VERSION "PT_K"

NS_ :

BS_:

BU_: BMS

BO_ 3221225472 VECTOR__INDEPENDENT_SIG_MSG: 0 Vector__XXX
 SG_ HVBTBDCSRQ_DlChDStReq : 0|4@0+ (1,0) [0|15] "" Vector__XXX
 SG_ HVBTBDCSRQ_DlChHStReq : 0|5@0+ (1,0) [0|31] "hr" Vector__XXX
 SG_ HVBTBDCSRQ_DlChMHStReq : 0|6@0+ (1,0) [0|63] "min" Vector__XXX
 SG_ HVBTBDCSRQ_DlChSsnStReq : 0|2@0+ (1,0) [0|3] "" Vector__XXX
 SG_ HVBTBDCSRQ_DlChSlStReq : 0|4@0+ (1,0) [0|15] "" Vector__XXX
 SG_ HVBTBRCSR_RtChDStReq : 0|4@0+ (1,0) [0|15] "" Vector__XXX
 SG_ HVBTBRCSR_RtChHStReq : 0|5@0+ (1,0) [0|31] "hr" Vector__XXX
 SG_ HVBTBRCSR_RtChMHStReq : 0|6@0+ (1,0) [0|63] "min" Vector__XXX
 SG_ HVBTBRCSR_RtChSsnStReq : 0|2@0+ (1,0) [0|3] "" Vector__XXX
 SG_ HVBTBRCSR_RtChSlRtStReq : 0|4@0+ (1,0) [0|15] "" Vector__XXX
 SG_ HVBTBRCSR_RtChSlStReq : 0|3@0+ (1,0) [0|7] "" Vector__XXX
 SG_ HVBTBRCSR_RtChSlTbRwReq : 0|3@0+ (1,0) [0|7] "rows" Vector__XXX

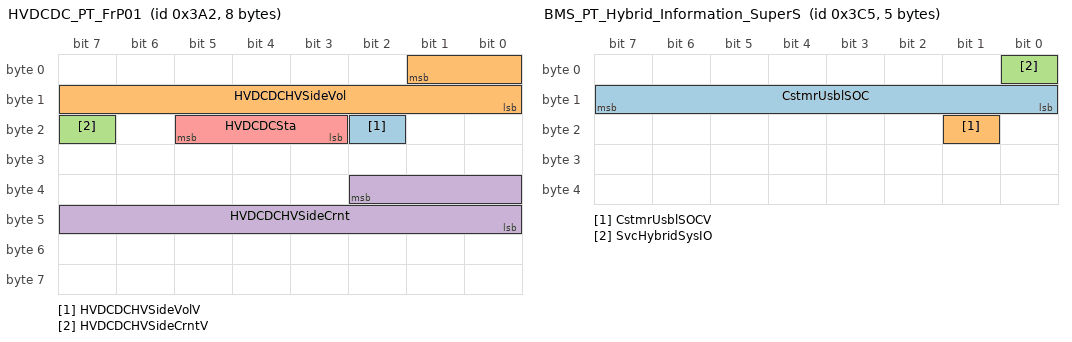
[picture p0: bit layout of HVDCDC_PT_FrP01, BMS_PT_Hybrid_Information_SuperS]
BO_ 930 HVDCDC_PT_FrP01: 8 Vector__XXX
 SG_ HVDCDCHVSideVolV : 18|1@0+ (1,0) [0|0] "l/min" Vector__XXX
 SG_ HVDCDCHVSideVol : 1|10@0+ (1,0) [0|0] "l/min" Vector__XXX
 SG_ HVDCDCHVSideCrntV : 23|1@0+ (1,0) [0|0] "l/min" Vector__XXX
 SG_ HVDCDCHVSideCrnt : 34|11@0+ (1,0) [0|0] "l/min" Vector__XXX
 SG_ HVDCDCSta : 21|3@0+ (1,0) [0|0] "l/min" Vector__XXX

BO_ 175 HCU_PT_FrP00: 8 Vector__XXX
 SG_ EPTStCmdOn : 17|1@0+ (1,0) [0|25.5] "l/min" Vector__XXX

BO_ 965 BMS_PT_Hybrid_Information_SuperS: 5 BMS
 SG_ CstmrUsblSOC : 15|8@0+ (0.39216,0) [0|100.0008] "%" Vector__XXX
 SG_ CstmrUsblSOCV : 17|1@0+ (1,0) [0|1] "" Vector__XXX
 SG_ SvcHybridSysIO : 0|1@0+ (1,0) [0|1] "" Vector__XXX

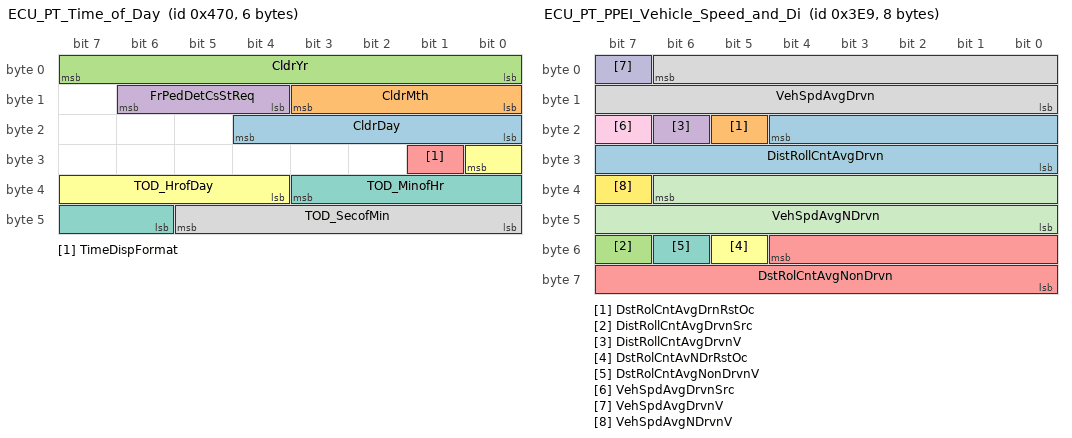
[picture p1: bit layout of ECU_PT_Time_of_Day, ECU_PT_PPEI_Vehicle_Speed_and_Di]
BO_ 1136 ECU_PT_Time_of_Day: 6 Vector__XXX
 SG_ CldrDay : 20|5@0+ (1,0) [0|31] "days"  BMS
 SG_ CldrMth : 11|4@0+ (1,0) [0|15] ""  BMS
 SG_ CldrYr : 7|8@0+ (1,2000) [2000|2255] "year"  BMS
 SG_ FrPedDetCsStReq : 14|3@0+ (1,0) [0|7] ""  BMS
 SG_ TimeDispFormat : 25|1@0+ (1,0) [0|1] ""  BMS
 SG_ TOD_HrofDay : 24|5@0+ (1,0) [0|31] "hr"  BMS
 SG_ TOD_MinofHr : 35|6@0+ (1,0) [0|63] "min"  BMS
 SG_ TOD_SecofMin : 45|6@0+ (1,0) [0|63] "s"  BMS

BO_ 497 ECU_PT_PPEI_Platform_General_Sta: 8 Vector__XXX
 SG_ ACCmpsrFldOn : 63|1@0+ (1,0) [0|1] ""  BMS
 SG_ ACCompModReq : 12|2@0+ (1,0) [0|3] ""  BMS
 SG_ ACCompNormLd : 55|8@0+ (0.1,0) [0|25.5] "l/min"  BMS
 SG_ ACCompNormLdV : 10|1@0+ (1,0) [0|1] ""  BMS
 SG_ SIRDpl : 58|1@0+ (1,0) [0|1] ""  BMS
 SG_ DispMeasSys : 59|1@0+ (1,0) [0|1] ""  BMS
 SG_ ElvtdIdlCstStReq : 33|2@0+ (1,0) [0|3] ""  BMS
 SG_ EngOilLfRstRq : 37|1@0+ (1,0) [0|1] ""  BMS
 SG_ FuelFltLfRstRqd : 56|1@0+ (1,0) [0|1] ""  BMS
 SG_ ImmblzrPreRelPswrd : 23|16@0+ (1,0) [0|65535] "passwrd"  BMS
 SG_ ImmblzrPreRelPswdStat : 8|1@0+ (1,0) [0|1] ""  BMS
 SG_ PrkBrkSwAtv : 36|1@0+ (1,0) [0|1] ""  BMS
 SG_ PMMAccTrmSt : 2|1@0+ (1,0) [0|1] ""  BMS
 SG_ PMMRunCrkTrmSt : 3|1@0+ (1,0) [0|1] ""  BMS
 SG_ RmVehStrRq : 15|1@0+ (1,0) [0|1] ""  BMS
 SG_ SysBkUpPwrMd : 5|2@0+ (1,0) [0|3] ""  BMS
 SG_ SysBkupPwrMdEn : 6|1@0+ (1,0) [0|1] ""  BMS
 SG_ SysBkUpPwrMdV : 46|1@0+ (1,0) [0|1] ""  BMS
 SG_ SysPwrMd : 1|2@0+ (1,0) [0|3] ""  BMS
 SG_ SysPwrMdV : 47|1@0+ (1,0) [0|1] ""  BMS
 SG_ ThrtlPrgrsnReq : 39|2@0+ (1,0) [0|3] ""  BMS
 SG_ TrStLgMdAtv : 34|1@0+ (1,0) [0|1] ""  BMS
 SG_ BkupPwrModeMstrVDA : 62|1@0+ (1,0) [0|1] ""  BMS
 SG_ ACCompSysVDA : 61|1@0+ (1,0) [0|1] ""  BMS
 SG_ AirbgVDA : 60|1@0+ (1,0) [0|1] ""  BMS

BO_ 1001 ECU_PT_PPEI_Vehicle_Speed_and_Di: 8 Vector__XXX
 SG_ DistRollCntAvgDrvn : 20|13@0+ (0.125,0) [0|1023.875] "m"  BMS
 SG_ DstRolCntAvgDrnRstOc : 21|1@0+ (1,0) [0|1] ""  BMS
 SG_ DistRollCntAvgDrvnSrc : 55|1@0+ (1,0) [0|1] ""  BMS
 SG_ DistRollCntAvgDrvnV : 22|1@0+ (1,0) [0|1] ""  BMS
 SG_ DstRolCntAvgNonDrvn : 52|13@0+ (0.125,0) [0|1023.875] "m"  BMS
 SG_ DstRolCntAvNDrRstOc : 53|1@0+ (1,0) [0|1] ""  BMS
 SG_ DstRolCntAvgNonDrvnV : 54|1@0+ (1,0) [0|1] ""  BMS
 SG_ VehSpdAvgDrvn : 6|15@0+ (0.015625,0) [0|511.984375] "km/h"  BMS
 SG_ VehSpdAvgDrvnSrc : 23|1@0+ (1,0) [0|1] ""  BMS
 SG_ VehSpdAvgDrvnV : 7|1@0+ (1,0) [0|1] ""  BMS
 SG_ VehSpdAvgNDrvn : 38|15@0+ (0.015625,0) [0|511.984375] "km/h"  BMS
 SG_ VehSpdAvgNDrvnV : 39|1@0+ (1,0) [0|1] ""  BMS

BO_ 288 ECU_PT_Vehicle_Odometer_HS: 5 Vector__XXX
 SG_ VehOdo : 7|32@0+ (0.015625,0) [0|67108863.984375] "km"  BMS
 SG_ VehOdoV : 32|1@0+ (1,0) [0|1] ""  BMS

BO_ 566 BMS_PT_VICM_Status_HS: 6 BMS
 SG_ ChrgSysAudblIndRq : 39|3@0+ (1,0) [0|7] "" Vector__XXX

BO_ 274 BMS_PT_Charging_Sys_Trans_Shift_: 5 BMS
 SG_ HVChrgPwrLvl : 22|3@0+ (1,0) [0|7] "" Vector__XXX

BO_ 326 BMS_PT_Energy_Storage_System: 8 BMS
 SG_ DrvCycElEnrgUsd : 21|14@0+ (0.36,0) [0|5897.88] "MJ" Vector__XXX

BO_ 1302 BMS_PT_High_Volt_Bat_Time_Bsd_Rs: 7 BMS
 SG_ HVBatCrgDspStat : 6|3@0+ (1,0) [0|7] "" Vector__XXX

BO_ 1078 BMS_PT_High_Volt_Time_Based_Chrg: 8 BMS
 SG_ TODCDMPTO_TpOvR : 51|4@0+ (1,0) [0|15] "" Vector__XXX

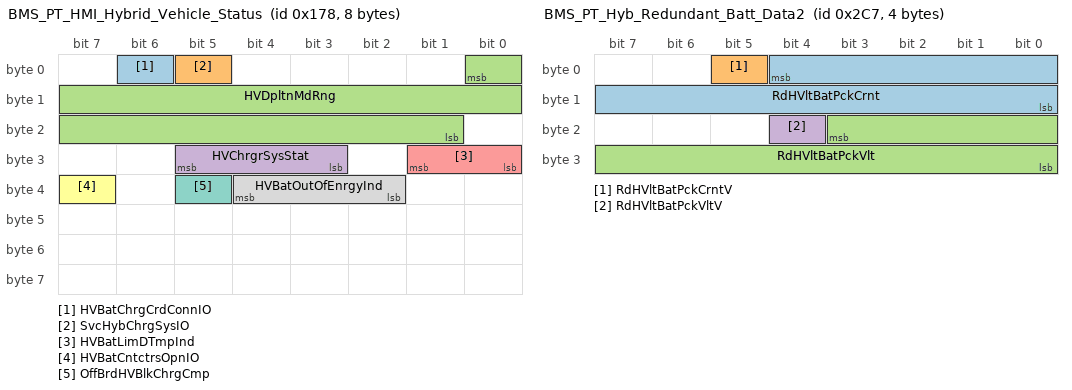
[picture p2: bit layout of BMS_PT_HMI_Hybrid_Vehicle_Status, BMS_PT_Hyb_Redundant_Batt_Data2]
BO_ 376 BMS_PT_HMI_Hybrid_Vehicle_Status: 8 BMS
 SG_ HVBatChrgCrdConnIO : 6|1@0+ (1,0) [0|1] "" Vector__XXX
 SG_ SvcHybChrgSysIO : 5|1@0+ (1,0) [0|1] "" Vector__XXX
 SG_ HVDpltnMdRng : 0|16@0+ (0.015625,0) [0|1023.984375] "km" Vector__XXX
 SG_ HVChrgrSysStat : 29|3@0+ (1,0) [0|7] "" Vector__XXX
 SG_ HVBatLimDTmpInd : 25|2@0+ (1,0) [0|3] "" Vector__XXX
 SG_ HVBatCntctrsOpnIO : 39|1@0+ (1,0) [0|1] "" Vector__XXX
 SG_ OffBrdHVBlkChrgCmp : 37|1@0+ (1,0) [0|1] "" Vector__XXX
 SG_ HVBatOutOfEnrgyInd : 36|3@0+ (1,0) [0|7] "" Vector__XXX

BO_ 711 BMS_PT_Hyb_Redundant_Batt_Data2: 4 BMS
 SG_ RdHVltBatPckCrnt : 4|13@0- (0.15,0) [-614.4|614.25] "A" Vector__XXX
 SG_ RdHVltBatPckCrntV : 5|1@0+ (1,0) [0|1] "" Vector__XXX
 SG_ RdHVltBatPckVlt : 19|12@0+ (0.125,0) [0|511.875] "V" Vector__XXX
 SG_ RdHVltBatPckVltV : 20|1@0+ (1,0) [0|1] "" Vector__XXX

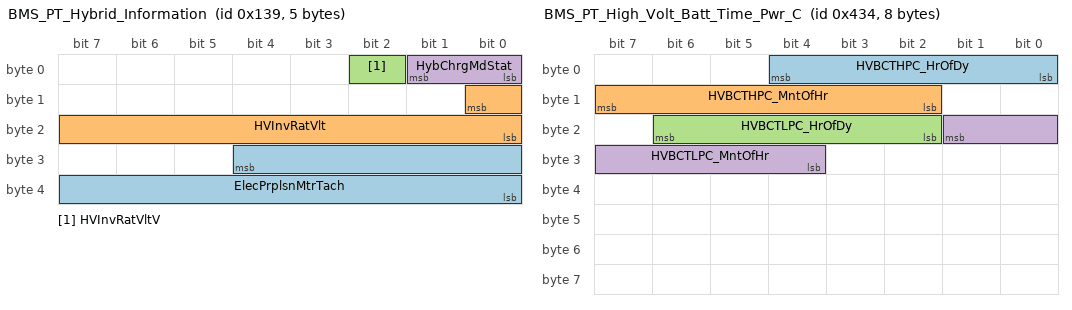
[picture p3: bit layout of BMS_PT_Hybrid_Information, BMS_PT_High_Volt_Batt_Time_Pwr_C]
BO_ 313 BMS_PT_Hybrid_Information: 5 BMS
 SG_ ElecPrplsnMtrTach : 28|13@0+ (1,0) [0|8191] "rpm" Vector__XXX
 SG_ HVInvRatVlt : 8|9@0+ (1,0) [0|511] "volts" Vector__XXX
 SG_ HVInvRatVltV : 2|1@0+ (1,0) [0|1] "" Vector__XXX
 SG_ HybChrgMdStat : 1|2@0+ (1,0) [0|3] "" Vector__XXX

BO_ 1298 BMS_PT_High_Volt_Bat_Time_B_0000: 8 BMS
 SG_ OBHVBCMinsRmng : 5|6@0+ (1,0) [0|63] "" Vector__XXX

BO_ 549 BMS_PT_Drive_Cycle_Efficiency: 8 BMS
 SG_ DTD_DrvCyclDstTrvld : 37|17@0+ (0.015625,0) [0|2047.984375] "km" Vector__XXX

BO_ 1076 BMS_PT_High_Volt_Batt_Time_Pwr_C: 8 BMS
 SG_ HVBCTHPC_HrOfDy : 4|5@0+ (1,0) [0|31] "Hour" Vector__XXX
 SG_ HVBCTHPC_MntOfHr : 15|6@0+ (1,0) [0|63] "Minute" Vector__XXX
 SG_ HVBCTLPC_HrOfDy : 22|5@0+ (1,0) [0|31] "Hour" Vector__XXX
 SG_ HVBCTLPC_MntOfHr : 17|6@0+ (1,0) [0|63] "Minute" Vector__XXX

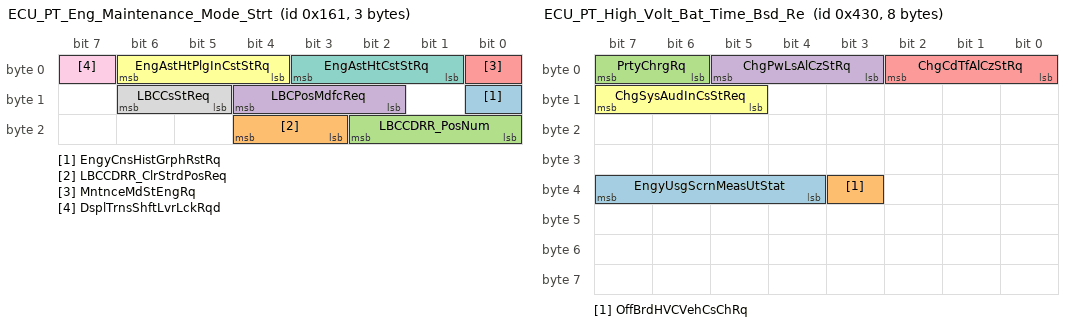
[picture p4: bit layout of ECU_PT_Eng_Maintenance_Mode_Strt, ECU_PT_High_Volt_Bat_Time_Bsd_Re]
BO_ 353 ECU_PT_Eng_Maintenance_Mode_Strt: 3 Vector__XXX
 SG_ EngyCnsHistGrphRstRq : 8|1@0+ (1,0) [0|1] ""  BMS
 SG_ LBCCDRR_ClrStrdPosReq : 20|2@0+ (1,0) [0|3] ""  BMS
 SG_ LBCCDRR_PosNum : 18|3@0+ (1,0) [0|7] ""  BMS
 SG_ LBCPosMdfcReq : 12|3@0+ (1,0) [0|7] ""  BMS
 SG_ MntnceMdStEngRq : 0|1@0+ (1,0) [0|1] ""  BMS
 SG_ EngAstHtPlgInCstStRq : 6|3@0+ (1,0) [0|7] ""  BMS
 SG_ EngAstHtCstStRq : 3|3@0+ (1,0) [0|7] ""  BMS
 SG_ LBCCsStReq : 14|2@0+ (1,0) [0|3] ""  BMS
 SG_ DsplTrnsShftLvrLckRqd : 7|1@0+ (1,0) [0|1] ""  BMS

BO_ 1072 ECU_PT_High_Volt_Bat_Time_Bsd_Re: 8 Vector__XXX
 SG_ EngyUsgScrnMeasUtStat : 39|4@0+ (1,0) [0|15] ""  BMS
 SG_ OffBrdHVCVehCsChRq : 35|1@0+ (1,0) [0|1] ""  BMS
 SG_ PrtyChrgRq : 7|2@0+ (1,0) [0|3] ""  BMS
 SG_ ChgPwLsAlCzStRq : 5|3@0+ (1,0) [0|7] ""  BMS
 SG_ ChgCdTfAlCzStRq : 2|3@0+ (1,0) [0|7] ""  BMS
 SG_ ChgSysAudInCsStReq : 15|3@0+ (1,0) [0|7] ""  BMS

BO_ 2430336753 DIAG_Func_USDT_Req_to_All_F_Test: 8 Vector__XXX
 SG_ DgnInf : 7|64@0+ (1,0) [0|1.84467440737096E+019] ""  BMS

BO_ 2430336755 DIAG_Func_USDT_Req_to_All_F_ONST: 8 Vector__XXX
 SG_ DgnInf : 7|64@0+ (1,0) [0|1.84467440737096E+019] ""  BMS

BO_ 2497360113 DIAG_Phy_USDT_Req_to_BMS_F_TestT: 8 Vector__XXX
 SG_ DgnInf : 7|64@0+ (1,0) [0|1.84467440737096E+019] ""  BMS

BO_ 2497360115 DIAG_Phy_USDT_Req_to_BMS_F_ONSTA: 8 Vector__XXX
 SG_ DgnInf : 7|64@0+ (1,0) [0|1.84467440737096E+019] ""  BMS

BO_ 2497376688 DIAG_Phy_USDT_Resp_F_BMS_To_Test: 8 BMS
 SG_ DgnInf : 7|64@0+ (1,0) [0|1.84467440737096E+019] "" Vector__XXX

BO_ 2497507760 BMS_PT_UUDT_Resp_TestTool: 8 BMS
 SG_ DgnInf : 7|64@0+ (1,0) [0|1.84467440737096E+019] "" Vector__XXX

BO_ 2497377200 DIAG_Phy_USDT_Resp_F_BMS_To_ONST: 8 BMS
 SG_ DgnInf : 7|64@0+ (1,0) [0|1.84467440737096E+019] "" Vector__XXX

BO_ 2497508272 BMS_PT_UUDT_Resp_ONSTAR: 8 BMS
 SG_ DgnInf : 7|64@0+ (1,0) [0|1.84467440737096E+019] "" Vector__XXX

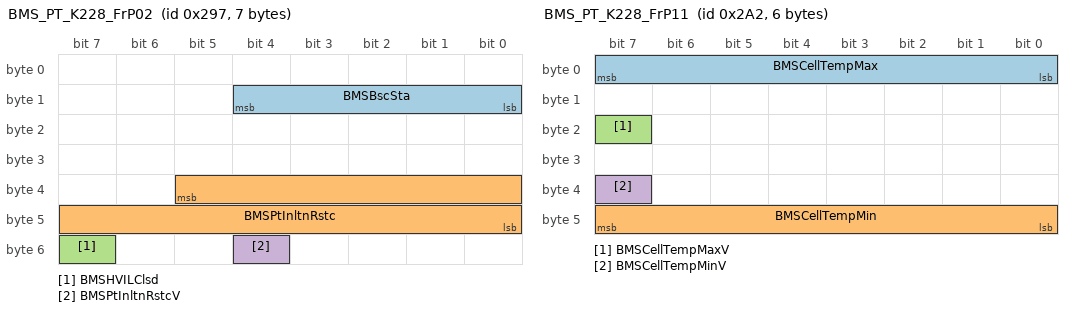
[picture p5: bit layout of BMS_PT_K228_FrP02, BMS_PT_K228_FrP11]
BO_ 663 BMS_PT_K228_FrP02: 7 BMS
 SG_ BMSBscSta : 12|5@0+ (1,0) [0|31] "" Vector__XXX
 SG_ BMSPtInltnRstc : 37|14@0+ (0.5,0) [0|8191] "kΩ" Vector__XXX
 SG_ BMSHVILClsd : 55|1@0+ (1,0) [0|1] "" Vector__XXX
 SG_ BMSPtInltnRstcV : 52|1@0+ (1,0) [0|1] "" Vector__XXX

BO_ 674 BMS_PT_K228_FrP11: 6 BMS
 SG_ BMSCellTempMax : 7|8@0+ (0.5,-40) [-40|87.5] "" Vector__XXX
 SG_ BMSCellTempMin : 47|8@0+ (0.5,-40) [-40|87.5] "" Vector__XXX
 SG_ BMSCellTempMaxV : 23|1@0+ (1,0) [0|1] "" Vector__XXX
 SG_ BMSCellTempMinV : 39|1@0+ (1,0) [0|1] "" Vector__XXX

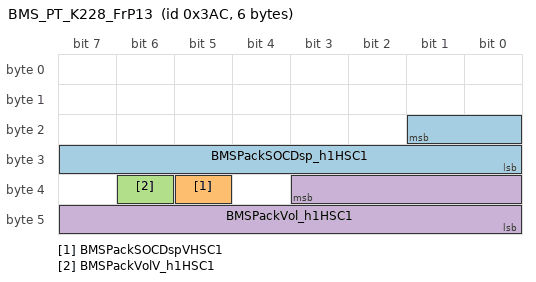
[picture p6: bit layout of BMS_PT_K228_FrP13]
BO_ 940 BMS_PT_K228_FrP13: 6 BMS
 SG_ BMSPackSOCDsp_h1HSC1 : 17|10@0+ (0.1,0) [0|102.3] "%" Vector__XXX
 SG_ BMSPackSOCDspVHSC1 : 37|1@0+ (1,0) [0|1] "" Vector__XXX
 SG_ BMSPackVolV_h1HSC1 : 38|1@0+ (1,0) [0|1] "" Vector__XXX
 SG_ BMSPackVol_h1HSC1 : 35|12@0+ (0.25,0) [0|1023.75] "V" Vector__XXX

CM_ BO_ 3221225472 "This is a message for not used signals, created by Vector CANdb++ DBC OLE DB Provider.";
BA_DEF_ BO_  "GenMsgSendType" ENUM  "cycle","triger","vector_leerstring";
BA_DEF_ BO_  "GenMsgCycleTime" INT 0 10000;
BA_DEF_  "BusType" STRING ;
BA_DEF_  "DBName" STRING ;
BA_DEF_ BO_  "SystemMessageLongSymbol" STRING ;
BA_DEF_DEF_  "GenMsgSendType" "cycle";
BA_DEF_DEF_  "GenMsgCycleTime" 200;
BA_DEF_DEF_  "BusType" "CAN";
BA_DEF_DEF_  "DBName" "";
BA_DEF_DEF_  "SystemMessageLongSymbol" "";
BA_ "DBName" "HS";
BA_ "GenMsgCycleTime" BO_ 930 100;
BA_ "GenMsgCycleTime" BO_ 175 10;
BA_ "GenMsgCycleTime" BO_ 965 250;
BA_ "SystemMessageLongSymbol" BO_ 965 "BMS_PT_Hybrid_Information_SuperSlow1";
BA_ "GenMsgCycleTime" BO_ 1136 1000;
BA_ "GenMsgCycleTime" BO_ 497 100;
BA_ "SystemMessageLongSymbol" BO_ 497 "ECU_PT_PPEI_Platform_General_Status_HS";
BA_ "GenMsgCycleTime" BO_ 1001 10;
BA_ "SystemMessageLongSymbol" BO_ 1001 "ECU_PT_PPEI_Vehicle_Speed_and_Distance_HS";
BA_ "GenMsgCycleTime" BO_ 288 1000;
BA_ "GenMsgCycleTime" BO_ 566 100;
BA_ "GenMsgCycleTime" BO_ 274 1000;
BA_ "SystemMessageLongSymbol" BO_ 274 "BMS_PT_Charging_Sys_Trans_Shift_Lock";
BA_ "GenMsgCycleTime" BO_ 326 1000;
BA_ "GenMsgCycleTime" BO_ 1302 1000;
BA_ "SystemMessageLongSymbol" BO_ 1302 "BMS_PT_High_Volt_Bat_Time_Bsd_Rsp_1";
BA_ "GenMsgCycleTime" BO_ 1078 1000;
BA_ "GenMsgCycleTime" BO_ 376 1000;
BA_ "GenMsgCycleTime" BO_ 711 1000;
BA_ "GenMsgCycleTime" BO_ 313 250;
BA_ "GenMsgCycleTime" BO_ 1298 0;
BA_ "SystemMessageLongSymbol" BO_ 1298 "BMS_PT_High_Volt_Bat_Time_Bsd_Rsp";
BA_ "GenMsgCycleTime" BO_ 549 0;
BA_ "GenMsgCycleTime" BO_ 1076 0;
BA_ "SystemMessageLongSymbol" BO_ 1076 "BMS_PT_High_Volt_Batt_Time_Pwr_Chrg";
BA_ "GenMsgCycleTime" BO_ 353 1000;
BA_ "SystemMessageLongSymbol" BO_ 353 "ECU_PT_Eng_Maintenance_Mode_Strt_Req";
BA_ "GenMsgCycleTime" BO_ 1072 1000;
BA_ "SystemMessageLongSymbol" BO_ 1072 "ECU_PT_High_Volt_Bat_Time_Bsd_Req";
BA_ "GenMsgCycleTime" BO_ 2430336753 0;
BA_ "SystemMessageLongSymbol" BO_ 2430336753 "DIAG_Func_USDT_Req_to_All_F_TestTool";
BA_ "GenMsgCycleTime" BO_ 2430336755 0;
BA_ "SystemMessageLongSymbol" BO_ 2430336755 "DIAG_Func_USDT_Req_to_All_F_ONSTAR";
BA_ "GenMsgCycleTime" BO_ 2497360113 0;
BA_ "SystemMessageLongSymbol" BO_ 2497360113 "DIAG_Phy_USDT_Req_to_BMS_F_TestTool";
BA_ "GenMsgCycleTime" BO_ 2497360115 0;
BA_ "SystemMessageLongSymbol" BO_ 2497360115 "DIAG_Phy_USDT_Req_to_BMS_F_ONSTAR";
BA_ "GenMsgCycleTime" BO_ 2497376688 0;
BA_ "SystemMessageLongSymbol" BO_ 2497376688 "DIAG_Phy_USDT_Resp_F_BMS_To_TestTool";
BA_ "GenMsgCycleTime" BO_ 2497507760 0;
BA_ "GenMsgCycleTime" BO_ 2497377200 0;
BA_ "SystemMessageLongSymbol" BO_ 2497377200 "DIAG_Phy_USDT_Resp_F_BMS_To_ONSTAR";
BA_ "GenMsgCycleTime" BO_ 2497508272 0;
BA_ "GenMsgCycleTime" BO_ 663 50;
BA_ "GenMsgCycleTime" BO_ 674 100;
BA_ "GenMsgCycleTime" BO_ 940 100;
VAL_ 3221225472 HVBTBDCSRQ_DlChDStReq 0 "No Action" 1 "Sunday" 2 "Monday" 3 "Tuesday" 4 "Wednsday" 5 "Thursday" 6 "Friday" 7 "Saturday" 8 "All Days Same" 9 "Mon - Fri Same" 10 "Sat & Sun Same" ;
VAL_ 3221225472 HVBTBDCSRQ_DlChSsnStReq 0 "No Action" 1 "Summer" 2 "Winter" 3 "Yearly" ;
VAL_ 3221225472 HVBTBDCSRQ_DlChSlStReq 0 "No Action" 1 "Departure Time 1" 2 "Reserved" 3 "Departure Time 1 Invalid" 4 "Reserved" 5 "Departure Time 2" 6 "Reserved" 7 "Departure Time 2 Invalid" 8 "Reserved" ;
VAL_ 3221225472 HVBTBRCSR_RtChDStReq 0 "No Action" 1 "Sunday" 2 "Monday" 3 "Tuesday" 4 "Wednsday" 5 "Thursday" 6 "Friday" 7 "Saturday" 8 "All Days Same" 9 "Mon - Fri Same" 10 "Sat & Sun Same" ;
VAL_ 3221225472 HVBTBRCSR_RtChSsnStReq 0 "No Action" 1 "Summer" 2 "Winter" 3 "Yearly" ;
VAL_ 3221225472 HVBTBRCSR_RtChSlRtStReq 0 "No Action" 1 "Low Rate" 2 "Medium Rate" 3 "High Rate" 4 "Reserved 1" 5 "Invalid Rate" ;
VAL_ 3221225472 HVBTBRCSR_RtChSlStReq 0 "No Action" 1 "Charge Start" 2 "Charge End" 3 "Charge Start Invalid" 4 "Charge End Invalid" ;
VAL_ 965 CstmrUsblSOCV 0 "Valid" 1 "Invalid" ;
VAL_ 965 SvcHybridSysIO 0 "False" 1 "True" ;
VAL_ 1136 CldrMth 0 "Unknown" 1 "January" 2 "February" 3 "March" 4 "April" 5 "May" 6 "June" 7 "July" 8 "August" 9 "September" 10 "October" 11 "November" 12 "December" ;
VAL_ 1136 FrPedDetCsStReq 0 "No Action" 1 "Off" 2 "Alert" 3 "Alert and Brake" ;
VAL_ 1136 TimeDispFormat 0 "12 hour mode" 1 "24 hour mode" ;
VAL_ 497 ACCmpsrFldOn 0 "False" 1 "True" ;
VAL_ 497 ACCompModReq 0 "Disengage Immediately" 1 "Disengage" 2 "Engage" 3 "No Action" ;
VAL_ 497 ACCompNormLdV 0 "Valid" 1 "Invalid" ;
VAL_ 497 SIRDpl 0 "False" 1 "True" ;
VAL_ 497 DispMeasSys 0 "Metric" 1 "English" ;
VAL_ 497 ElvtdIdlCstStReq 0 "No Action" 1 "Off" 2 "On" ;
VAL_ 497 EngOilLfRstRq 0 "False" 1 "True" ;
VAL_ 497 FuelFltLfRstRqd 0 "False" 1 "True" ;
VAL_ 497 ImmblzrPreRelPswdStat 0 "No Information" 1 "Information Valid" ;
VAL_ 497 PrkBrkSwAtv 0 "False" 1 "True" ;
VAL_ 497 PMMAccTrmSt 0 "Inactive" 1 "Active" ;
VAL_ 497 PMMRunCrkTrmSt 0 "Inactive" 1 "Active" ;
VAL_ 497 RmVehStrRq 0 "Remote Start Not Requested" 1 "Remote Start Requested" ;
VAL_ 497 SysBkUpPwrMd 0 "Off" 1 "Accessory" 2 "Run" 3 "Crank Request" ;
VAL_ 497 SysBkupPwrMdEn 0 "False" 1 "True" ;
VAL_ 497 SysBkUpPwrMdV 0 "Valid" 1 "Invalid" ;
VAL_ 497 SysPwrMd 0 "Off" 1 "Accessory" 2 "Run" 3 "Crank Request" ;
VAL_ 497 SysPwrMdV 0 "Valid" 1 "Invalid" ;
VAL_ 497 ThrtlPrgrsnReq 0 "Map A" 1 "Map B" 2 "Map C" ;
VAL_ 497 TrStLgMdAtv 0 "False" 1 "True" ;
VAL_ 497 BkupPwrModeMstrVDA 0 "VirtualDeviceUnavailable" 1 "VirtualDeviceAvailable" ;
VAL_ 497 ACCompSysVDA 0 "VirtualDeviceUnavailable" 1 "VirtualDeviceAvailable" ;
VAL_ 497 AirbgVDA 0 "VirtualDeviceUnavailable" 1 "VirtualDeviceAvailable" ;
VAL_ 1001 DstRolCntAvgDrnRstOc 0 "False" 1 "True" ;
VAL_ 1001 DistRollCntAvgDrvnSrc 0 "Transmission Output Speed" 1 "Wheel Speed" ;
VAL_ 1001 DistRollCntAvgDrvnV 0 "Valid" 1 "Invalid" ;
VAL_ 1001 DstRolCntAvNDrRstOc 0 "False" 1 "True" ;
VAL_ 1001 DstRolCntAvgNonDrvnV 0 "Valid" 1 "Invalid" ;
VAL_ 1001 VehSpdAvgDrvnSrc 0 "Transmission Output Speed" 1 "Wheel Speed" ;
VAL_ 1001 VehSpdAvgDrvnV 0 "Valid" 1 "Invalid" ;
VAL_ 1001 VehSpdAvgNDrvnV 0 "Valid" 1 "Invalid" ;
VAL_ 288 VehOdoV 0 "Valid" 1 "Invalid" ;
VAL_ 566 ChrgSysAudblIndRq 0 "Inactive" 1 "Sequence 1" 2 "Sequence 2" 3 "Sequence 3" 4 "Sequence 4" 5 "Unused and Reserved1" 6 "Unused and Reserved2" 7 "Unused and Reserved3" ;
VAL_ 274 HVChrgPwrLvl 0 "Unavailable" 1 "AC Level1" 2 "AC Level2" 3 "DC" ;
VAL_ 1302 HVBatCrgDspStat 0 "Inactive" 1 "Pending" 2 "Active Charging" 3 "Complete" 4 "Faulted" ;
VAL_ 1078 TODCDMPTO_TpOvR 0 "None" 1 "Override Immediate" 2 "Override Next Plan Depart Time" 3 "Disabled" 4 "Onboard Fault" 5 "Offboard Fault Off Vehicle" 6 "Offboard Fault On Vehicle" 7 "Offboard Active" 8 "Offboard Not Active" 9 "Offboard Active Bulk Done" 10 "Offboard Not Active Bulk Done" 11 "Offboard Thermal Conditioning Only" ;
VAL_ 376 HVBatChrgCrdConnIO 1 "True" 0 "False" ;
VAL_ 376 SvcHybChrgSysIO 1 "True" 0 "False" ;
VAL_ 376 HVChrgrSysStat 0 "Default" 1 "Idle" 2 "Initializing" 3 "Active" 4 "Complete" 5 "Aborted" ;
VAL_ 376 HVBatLimDTmpInd 0 "Normal" 1 "Cold" 2 "Hot" ;
VAL_ 376 HVBatCntctrsOpnIO 1 "True" 0 "False" ;
VAL_ 376 OffBrdHVBlkChrgCmp 1 "True" 0 "False" ;
VAL_ 376 HVBatOutOfEnrgyInd 0 "No Action" 1 "Charge Vehicle Soon" 2 "Charge Vehicle Now" 3 "Out of Energy" ;
VAL_ 711 RdHVltBatPckCrntV 0 "Valid" 1 "Invalid" ;
VAL_ 711 RdHVltBatPckVltV 0 "Valid" 1 "Invalid" ;
VAL_ 313 HVInvRatVltV 0 "Valid" 1 "Invalid" ;
VAL_ 313 HybChrgMdStat 0 "Charge Depleting" 1 "Charge Sustaining" 2 "Unused and reserved 1" 3 "Unused and reserved 2" ;
VAL_ 353 EngyCnsHistGrphRstRq 0 "False" 1 "True" ;
VAL_ 353 LBCCDRR_ClrStrdPosReq 0 "No Action" 1 "Request to Clear Position" 2 "Confirmation to Clear Position" ;
VAL_ 353 LBCCDRR_PosNum 0 "No Action" 1 "Position Number 1" 2 "Position Number 2" 3 "Position Number 3" 4 "Position Number 4" ;
VAL_ 353 LBCPosMdfcReq 0 "No Action" 1 "Store Position 1" 2 "Store Position 2" 3 "Store Position 3" 4 "Store Position 4" ;
VAL_ 353 MntnceMdStEngRq 0 "False" 1 "True" ;
VAL_ 353 EngAstHtPlgInCstStRq 0 "No Action" 1 "Off" 2 "On" ;
VAL_ 353 EngAstHtCstStRq 0 "No Action" 1 "On" 2 "Deferred" ;
VAL_ 353 LBCCsStReq 0 "No Action" 1 "Off" 2 "On" ;
VAL_ 353 DsplTrnsShftLvrLckRqd 1 "True" 0 "False" ;
VAL_ 1072 EngyUsgScrnMeasUtStat 0 "No Action" 1 "MPG" 2 "MPGe Combined" 3 "L/100km" 4 "L/100km e Combined" 5 "km/L" 6 "km/L e Combined" 7 "Unused and Reserved 1" 8 "Unused and Reserved 2" 9 "Unused and Reserved 3" 10 "Unused and Reserved 4" 11 "Unused and Reserved 5" 12 "Unused and Reserved 6" 13 "Unused and Reserved 7" 14 "Unused and Reserved 8" 15 "Unused and Reserved 9" ;
VAL_ 1072 OffBrdHVCVehCsChRq 0 "False" 1 "True" ;
VAL_ 1072 PrtyChrgRq 0 "No Action" 1 "False" 2 "True" ;
VAL_ 1072 ChgPwLsAlCzStRq 0 "No Action" 1 "Off" 2 "On" 3 "Reserved 1" 4 "Reserved 2" 5 "Reserved 3" 6 "Reserved 4" 7 "Reserved 5" ;
VAL_ 1072 ChgCdTfAlCzStRq 0 "No Action" 1 "Off" 2 "On" 3 "Reserved 1" 4 "Reserved 2" 5 "Reserved 3" 6 "Reserved 4" 7 "Reserved 5" ;
VAL_ 1072 ChgSysAudInCsStReq 0 "No Action" 1 "Off" 2 "On" ;
VAL_ 663 BMSBscSta 0 "Power Up" 1 "Drive Ready" 2 "Drive Pre-charging" 3 "Drive Mode" 4 "On-board Charge Ready" 5 "Off-board Charge Ready" 6 "On-board Charging Mode" 7 "Off-board Charging Mode" 8 "Offline Balance" 9 "Off-board Charging Done" 10 "On-board Charging Done" 12 "On-board Pre-charging" 13 "Collision Mode" 14 "Balancing" 15 "Fault" ;
VAL_ 663 BMSHVILClsd 0 "Opened" 1 "Closed" ;
VAL_ 663 BMSPtInltnRstcV 0 "Valid" 1 "Invalid" ;
VAL_ 674 BMSCellTempMaxV 0 "Valid" 1 "Invalid" ;
VAL_ 674 BMSCellTempMinV 0 "Valid" 1 "Invalid" ;
SIG_GROUP_ 1136 TmofDay 1 : TOD_HrofDay TOD_MinofHr TOD_SecofMin;
SIG_GROUP_ 353 LBCCstmrDaRstReq 1 : LBCCDRR_ClrStrdPosReq LBCCDRR_PosNum;
